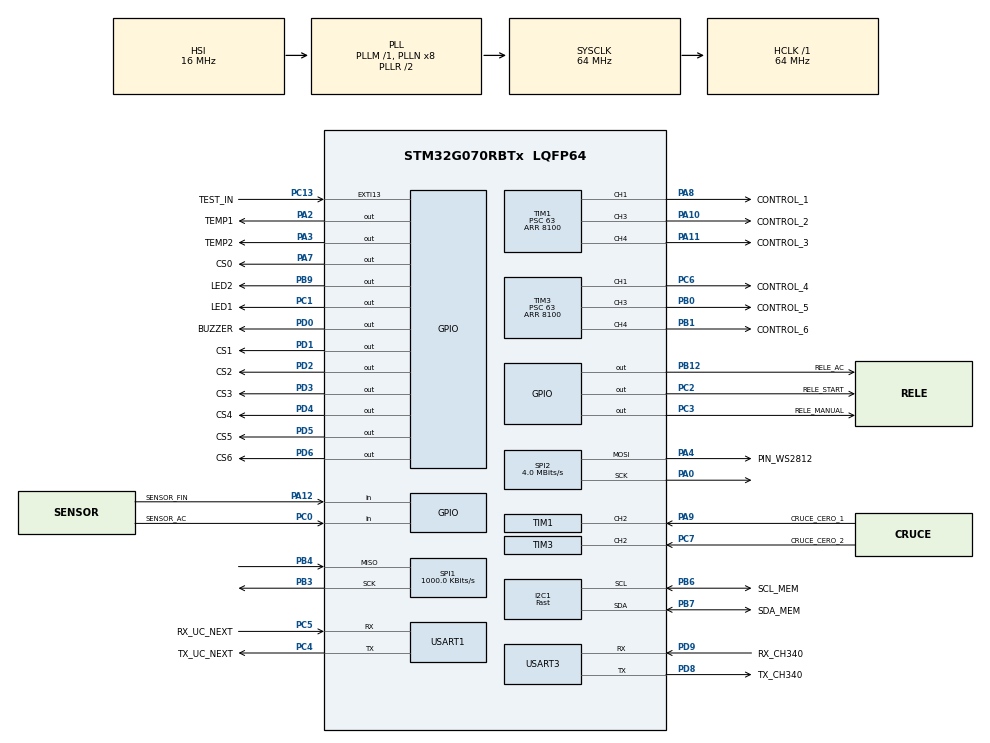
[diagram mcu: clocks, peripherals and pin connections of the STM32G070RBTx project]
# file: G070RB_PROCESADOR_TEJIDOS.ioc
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Dma.Request0=SPI2_TX
Dma.SPI2_TX.0.Direction=DMA_MEMORY_TO_PERIPH
Dma.SPI2_TX.0.EventEnable=DISABLE
Dma.SPI2_TX.0.Instance=DMA1_Channel1
Dma.SPI2_TX.0.MemDataAlignment=DMA_MDATAALIGN_BYTE
Dma.SPI2_TX.0.MemInc=DMA_MINC_ENABLE
Dma.SPI2_TX.0.Mode=DMA_NORMAL
Dma.SPI2_TX.0.PeriphDataAlignment=DMA_PDATAALIGN_BYTE
Dma.SPI2_TX.0.PeriphInc=DMA_PINC_DISABLE
Dma.SPI2_TX.0.Polarity=HAL_DMAMUX_REQ_GEN_RISING
Dma.SPI2_TX.0.Priority=DMA_PRIORITY_LOW
Dma.SPI2_TX.0.RequestNumber=1
Dma.SPI2_TX.0.SignalID=NONE
Dma.SPI2_TX.0.SyncEnable=DISABLE
Dma.SPI2_TX.0.SyncPolarity=HAL_DMAMUX_SYNC_NO_EVENT
Dma.SPI2_TX.0.SyncRequestNumber=1
Dma.SPI2_TX.0.SyncSignalID=NONE
I2C1.I2C_Speed_Mode=I2C_Fast
I2C1.Timing=0x00C12166
IWDG.Prescaler=IWDG_PRESCALER_256
IWDG.Reload=2000
Mcu.Family=STM32G0
Mcu.Name=STM32G070RBTx
Mcu.Package=LQFP64
NVIC.DMA1_Channel1_IRQn=true\:0\:0\:false\:false\:true\:false\:true\:true
NVIC.EXTI4_15_IRQn=true\:0\:0\:false\:false\:true\:true\:true\:true
NVIC.TIM14_IRQn=true\:0\:0\:false\:false\:true\:true\:true\:true
NVIC.TIM16_IRQn=true\:0\:0\:false\:false\:true\:true\:true\:true
NVIC.TIM1_BRK_UP_TRG_COM_IRQn=true\:0\:0\:false\:false\:true\:true\:true\:true
NVIC.TIM1_CC_IRQn=true\:0\:0\:false\:false\:true\:true\:true\:true
NVIC.TIM3_IRQn=true\:0\:0\:false\:false\:true\:true\:true\:true
NVIC.TIM6_IRQn=true\:0\:0\:false\:false\:true\:true\:true\:true
NVIC.TIM7_IRQn=true\:0\:0\:false\:false\:true\:true\:true\:true
NVIC.USART1_IRQn=true\:0\:0\:false\:false\:true\:true\:true\:true
NVIC.USART3_4_IRQn=true\:0\:0\:false\:false\:true\:true\:true\:true
PA0.Mode=TX_Only_Simplex_Unidirect_Master
PA0.Signal=SPI2_SCK
PA10.GPIO_Label=CONTROL_2
PA10.Signal=S_TIM1_CH3
PA11\ [PA9].GPIO_Label=CONTROL_3
PA11\ [PA9].Signal=S_TIM1_CH4
PA12\ [PA10].GPIO_Label=SENSOR_FIN
PA12\ [PA10].Signal=GPIO_Input
PA13.Mode=Serial_Wire
PA13.Signal=SYS_SWDIO
PA14-BOOT0.Mode=Serial_Wire
PA14-BOOT0.Signal=SYS_SWCLK
PA2.GPIO_Label=TEMP1
PA2.GPIO_ModeDefaultOutputPP=GPIO_MODE_OUTPUT_OD
PA2.GPIO_PuPd=GPIO_NOPULL
PA2.Signal=GPIO_Output
PA3.GPIO_Label=TEMP2
PA3.GPIO_ModeDefaultOutputPP=GPIO_MODE_OUTPUT_OD
PA3.GPIO_PuPd=GPIO_NOPULL
PA3.Signal=GPIO_Output
PA4.GPIO_Label=PIN_WS2812
PA4.Mode=TX_Only_Simplex_Unidirect_Master
PA4.Signal=SPI2_MOSI
PA7.GPIO_Label=CS0
PA7.Signal=GPIO_Output
PA8.GPIO_Label=CONTROL_1
PA8.Signal=S_TIM1_CH1
PA9.GPIO_Label=CRUCE_CERO_1
PA9.Signal=S_TIM1_CH2
PB0.GPIO_Label=CONTROL_5
PB0.Signal=S_TIM3_CH3
PB1.GPIO_Label=CONTROL_6
PB1.Signal=S_TIM3_CH4
PB12.GPIO_Label=RELE_AC
PB12.Signal=GPIO_Output
PB3.Mode=RX_Only_Simplex_Unidirect_Master
PB3.Signal=SPI1_SCK
PB4.Mode=RX_Only_Simplex_Unidirect_Master
PB4.Signal=SPI1_MISO
PB6.GPIO_Label=SCL_MEM
PB6.Mode=I2C
PB6.Signal=I2C1_SCL
PB7.GPIO_Label=SDA_MEM
PB7.Mode=I2C
PB7.Signal=I2C1_SDA
PB9.GPIO_Label=LED2
PB9.Signal=GPIO_Output
PC0.GPIO_Label=SENSOR_AC
PC0.Signal=GPIO_Input
PC1.GPIO_Label=LED1
PC1.Signal=GPIO_Output
PC13.GPIO_Label=TEST_IN
PC13.GPIO_ModeDefaultEXTI=GPIO_MODE_IT_FALLING
PC13.Signal=GPXTI13
PC14-OSC32_IN\ (PC14).Mode=LSE-External-Oscillator
PC14-OSC32_IN\ (PC14).Signal=RCC_OSC32_IN
PC15-OSC32_OUT\ (PC15).Mode=LSE-External-Oscillator
PC15-OSC32_OUT\ (PC15).Signal=RCC_OSC32_OUT
PC2.GPIO_Label=RELE_START
PC2.Signal=GPIO_Output
PC3.GPIO_Label=RELE_MANUAL
PC3.Signal=GPIO_Output
PC4.GPIO_Label=TX_UC_NEXT
PC4.Mode=Asynchronous
PC4.Signal=USART1_TX
PC5.GPIO_Label=RX_UC_NEXT
PC5.Mode=Asynchronous
PC5.Signal=USART1_RX
PC6.GPIO_Label=CONTROL_4
PC6.Signal=S_TIM3_CH1
PC7.GPIO_Label=CRUCE_CERO_2
PC7.Signal=S_TIM3_CH2
PD0.GPIO_Label=BUZZER
PD0.Signal=GPIO_Output
PD1.GPIO_Label=CS1
PD1.GPIO_ModeDefaultOutputPP=GPIO_MODE_OUTPUT_PP
PD1.GPIO_PuPd=GPIO_NOPULL
PD1.Signal=GPIO_Output
PD2.GPIO_Label=CS2
PD2.GPIO_ModeDefaultOutputPP=GPIO_MODE_OUTPUT_PP
PD2.GPIO_PuPd=GPIO_NOPULL
PD2.Signal=GPIO_Output
PD3.GPIO_Label=CS3
PD3.GPIO_ModeDefaultOutputPP=GPIO_MODE_OUTPUT_PP
PD3.GPIO_PuPd=GPIO_NOPULL
PD3.Signal=GPIO_Output
PD4.GPIO_Label=CS4
PD4.GPIO_ModeDefaultOutputPP=GPIO_MODE_OUTPUT_PP
PD4.GPIO_PuPd=GPIO_NOPULL
PD4.Signal=GPIO_Output
PD5.GPIO_Label=CS5
PD5.GPIO_ModeDefaultOutputPP=GPIO_MODE_OUTPUT_PP
PD5.GPIO_PuPd=GPIO_NOPULL
PD5.Signal=GPIO_Output
PD6.GPIO_Label=CS6
PD6.GPIO_ModeDefaultOutputPP=GPIO_MODE_OUTPUT_PP
PD6.GPIO_PuPd=GPIO_NOPULL
PD6.Signal=GPIO_Output
PD8.GPIO_Label=TX_CH340
PD8.Mode=Asynchronous
PD8.Signal=USART3_TX
PD9.GPIO_Label=RX_CH340
PD9.Mode=Asynchronous
PD9.Signal=USART3_RX
PF0-OSC_IN\ (PF0).Mode=HSE-External-Oscillator
PF0-OSC_IN\ (PF0).Signal=RCC_OSC_IN
PF1-OSC_OUT\ (PF1).Mode=HSE-External-Oscillator
PF1-OSC_OUT\ (PF1).Signal=RCC_OSC_OUT
ProjectManager.HeapSize=0x200
ProjectManager.StackSize=0x400
ProjectManager.TargetToolchain=STM32CubeIDE
RCC.ADCFreq_Value=64000000
RCC.AHBFreq_Value=64000000
RCC.CortexFreq_Value=64000000
RCC.EXTERNAL_CLOCK_VALUE=48000
RCC.HCLKFreq_Value=64000000
RCC.HSE_VALUE=8000000
RCC.HSI_VALUE=16000000
RCC.SYSCLKFreq_VALUE=64000000
RCC.SYSCLKSource=RCC_SYSCLKSOURCE_PLLCLK
RCC.VCOOutputFreq_Value=128000000
SH.S_TIM1_CH1.0=TIM1_CH1,PWM Generation1 CH1
SH.S_TIM1_CH2.0=TIM1_CH2,TriggerSource_TI2FP2
SH.S_TIM1_CH3.0=TIM1_CH3,PWM Generation3 CH3
SH.S_TIM1_CH4.0=TIM1_CH4,PWM Generation4 CH4
SH.S_TIM3_CH1.0=TIM3_CH1,PWM Generation1 CH1
SH.S_TIM3_CH2.0=TIM3_CH2,TriggerSource_TI2FP2
SH.S_TIM3_CH3.0=TIM3_CH3,PWM Generation3 CH3
SH.S_TIM3_CH4.0=TIM3_CH4,PWM Generation4 CH4
SPI1.BaudRatePrescaler=SPI_BAUDRATEPRESCALER_64
SPI1.CLKPhase=SPI_PHASE_1EDGE
SPI1.CalculateBaudRate=1000.0 KBits/s
SPI1.DataSize=SPI_DATASIZE_16BIT
SPI1.Direction=SPI_DIRECTION_2LINES_RXONLY
SPI1.FirstBit=SPI_FIRSTBIT_MSB
SPI1.Mode=SPI_MODE_MASTER
SPI1.VirtualType=VM_MASTER
SPI2.BaudRatePrescaler=SPI_BAUDRATEPRESCALER_16
SPI2.CalculateBaudRate=4.0 MBits/s
SPI2.DataSize=SPI_DATASIZE_8BIT
SPI2.Direction=SPI_DIRECTION_2LINES
SPI2.FirstBit=SPI_FIRSTBIT_LSB
SPI2.Mode=SPI_MODE_MASTER
SPI2.VirtualType=VM_MASTER
TIM1.Channel-PWM\ Generation1\ CH1=TIM_CHANNEL_1
TIM1.Channel-PWM\ Generation3\ CH3=TIM_CHANNEL_3
TIM1.Channel-PWM\ Generation4\ CH4=TIM_CHANNEL_4
TIM1.OCMode_PWM-PWM\ Generation1\ CH1=TIM_OCMODE_PWM2
TIM1.OCMode_PWM-PWM\ Generation3\ CH3=TIM_OCMODE_PWM2
TIM1.OCMode_PWM-PWM\ Generation4\ CH4=TIM_OCMODE_PWM2
TIM1.OCPolarity_1=TIM_OCPOLARITY_HIGH
TIM1.OCPolarity_3=TIM_OCPOLARITY_HIGH
TIM1.OCPolarity_4=TIM_OCPOLARITY_HIGH
TIM1.Period=8100
TIM1.Prescaler=63
TIM1.Pulse-PWM\ Generation1\ CH1=1
TIM1.Pulse-PWM\ Generation3\ CH3=1
TIM1.Pulse-PWM\ Generation4\ CH4=1
TIM1.TIM_MasterSlaveMode=TIM_MASTERSLAVEMODE_DISABLE
TIM14.Period=999
TIM14.Prescaler=63999
TIM16.Period=99
TIM16.Prescaler=6399
TIM17.Period=65535
TIM17.Prescaler=0
TIM3.Channel-PWM\ Generation1\ CH1=TIM_CHANNEL_1
TIM3.Channel-PWM\ Generation3\ CH3=TIM_CHANNEL_3
TIM3.Channel-PWM\ Generation4\ CH4=TIM_CHANNEL_4
TIM3.OCMode_PWM-PWM\ Generation1\ CH1=TIM_OCMODE_PWM2
TIM3.OCMode_PWM-PWM\ Generation3\ CH3=TIM_OCMODE_PWM2
TIM3.OCMode_PWM-PWM\ Generation4\ CH4=TIM_OCMODE_PWM2
TIM3.OCPolarity_1=TIM_OCPOLARITY_HIGH
TIM3.OCPolarity_3=TIM_OCPOLARITY_HIGH
TIM3.OCPolarity_4=TIM_OCPOLARITY_HIGH
TIM3.Period=8100
TIM3.Prescaler=63
TIM3.Pulse-PWM\ Generation1\ CH1=1
TIM3.Pulse-PWM\ Generation3\ CH3=1
TIM3.Pulse-PWM\ Generation4\ CH4=1
TIM6.Period=9999
TIM6.Prescaler=6399
TIM7.Period=29999
TIM7.Prescaler=63999
USART1.VirtualMode-Asynchronous=VM_ASYNC
USART3.VirtualMode-Asynchronous=VM_ASYNC
VP_IWDG_VS_IWDG.Mode=IWDG_Activate
VP_SYS_VS_DBSignals.Mode=DisableDeadBatterySignals
VP_TIM14_VS_ClockSourceINT.Mode=Enable_Timer
VP_TIM16_VS_ClockSourceINT.Mode=Enable_Timer
VP_TIM17_VS_ClockSourceINT.Mode=Enable_Timer
VP_TIM1_VS_ClockSourceINT.Mode=Internal
VP_TIM1_VS_ControllerModeCombinedResetTrigger.Mode=Combined_Reset_Trigger_Mode
VP_TIM3_VS_ClockSourceINT.Mode=Internal
VP_TIM3_VS_ControllerModeCombinedResetTrigger.Mode=Combined_Reset_Trigger_Mode
VP_TIM6_VS_ClockSourceINT.Mode=Enable_Timer
VP_TIM7_VS_ClockSourceINT.Mode=Enable_Timer
board=custom

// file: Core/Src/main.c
/* USER CODE BEGIN Header */
/**
  ******************************************************************************
  * @file           : main.c
  * @brief          : Main program body
  ******************************************************************************
  * @attention
  *
  * Copyright (c) 2025 STMicroelectronics.
  * All rights reserved.
  *
  * This software is licensed under terms that can be found in the LICENSE file
  * in the root directory of this software component.
  * If no LICENSE file comes with this software, it is provided AS-IS.
  *
  ******************************************************************************
  */
/* USER CODE END Header */
#include "main.h"
#include "dma.h"
#include "i2c.h"
#include "iwdg.h"
#include "spi.h"
#include "tim.h"
#include "usart.h"
#include "gpio.h"

/* USER CODE BEGIN Includes */
#include "string.h"
#include "MainCpp.h"
/* USER CODE END Includes */

void SystemClock_Config(void);

int main(void)
{

  /* MCU Configuration--------------------------------------------------------*/

  /* Reset of all peripherals, Initializes the Flash interface and the Systick. */
  HAL_Init();

  /* Configure the system clock */
  SystemClock_Config();

  /* Initialize all configured peripherals */
  MX_GPIO_Init();
  MX_DMA_Init();
  MX_SPI1_Init();
  MX_SPI2_Init();
  MX_TIM1_Init();
  MX_TIM3_Init();
  MX_TIM6_Init();
  MX_TIM16_Init();
  MX_I2C1_Init();
  MX_USART1_UART_Init();
  MX_USART3_UART_Init();
  MX_TIM7_Init();
  MX_TIM14_Init();
  MX_TIM17_Init();
#if ENG_STATE_MACH_WATCHDOG == 1
  MX_IWDG_Init();
#endif
  /* USER CODE BEGIN 2 */

  InitCpp();

  /* USER CODE END 2 */

  /* Infinite loop */
  while (1)
  {

    /* USER CODE BEGIN 3 */
	  MainCpp();
  }
  /* USER CODE END 3 */
}

void SystemClock_Config(void)
{
  RCC_OscInitTypeDef RCC_OscInitStruct = {0};
  RCC_ClkInitTypeDef RCC_ClkInitStruct = {0};

  /** Configure the main internal regulator output voltage
  */
  HAL_PWREx_ControlVoltageScaling(PWR_REGULATOR_VOLTAGE_SCALE1);

  /** Initializes the RCC Oscillators according to the specified parameters
  * in the RCC_OscInitTypeDef structure.
  */
  RCC_OscInitStruct.OscillatorType = RCC_OSCILLATORTYPE_HSI|RCC_OSCILLATORTYPE_LSI;
  RCC_OscInitStruct.HSIState = RCC_HSI_ON;
  RCC_OscInitStruct.HSIDiv = RCC_HSI_DIV1;
  RCC_OscInitStruct.HSICalibrationValue = RCC_HSICALIBRATION_DEFAULT;
  RCC_OscInitStruct.LSIState = RCC_LSI_ON;
  RCC_OscInitStruct.PLL.PLLState = RCC_PLL_ON;
  RCC_OscInitStruct.PLL.PLLSource = RCC_PLLSOURCE_HSI;
  RCC_OscInitStruct.PLL.PLLM = RCC_PLLM_DIV1;
  RCC_OscInitStruct.PLL.PLLN = 8;
  RCC_OscInitStruct.PLL.PLLP = RCC_PLLP_DIV2;
  RCC_OscInitStruct.PLL.PLLR = RCC_PLLR_DIV2;
  if (HAL_RCC_OscConfig(&RCC_OscInitStruct) != HAL_OK)
  {
    Error_Handler();
  }

  /** Initializes the CPU, AHB and APB buses clocks
  */
  RCC_ClkInitStruct.ClockType = RCC_CLOCKTYPE_HCLK|RCC_CLOCKTYPE_SYSCLK
                              |RCC_CLOCKTYPE_PCLK1;
  RCC_ClkInitStruct.SYSCLKSource = RCC_SYSCLKSOURCE_PLLCLK;
  RCC_ClkInitStruct.AHBCLKDivider = RCC_SYSCLK_DIV1;
  RCC_ClkInitStruct.APB1CLKDivider = RCC_HCLK_DIV1;

  if (HAL_RCC_ClockConfig(&RCC_ClkInitStruct, FLASH_LATENCY_2) != HAL_OK)
  {
    Error_Handler();
  }
}

void Error_Handler(void)
{
  __disable_irq();
  while (1)
  {
  }
}
